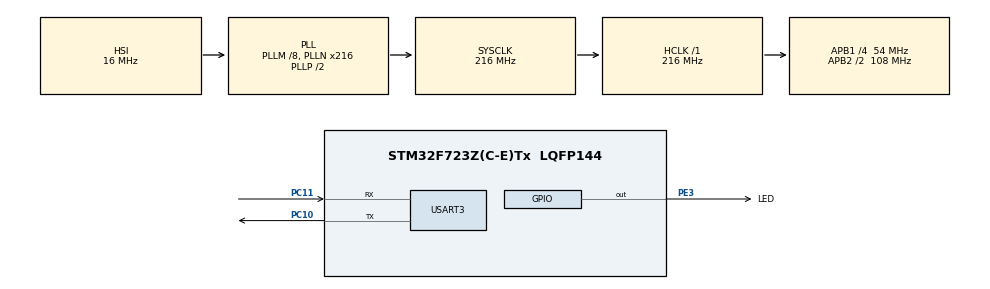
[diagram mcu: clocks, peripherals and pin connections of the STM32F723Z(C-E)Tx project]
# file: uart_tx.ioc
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Dma.Request0=USART3_TX
Dma.USART3_TX.0.Direction=DMA_MEMORY_TO_PERIPH
Dma.USART3_TX.0.FIFOMode=DMA_FIFOMODE_DISABLE
Dma.USART3_TX.0.Instance=DMA1_Stream3
Dma.USART3_TX.0.MemDataAlignment=DMA_MDATAALIGN_BYTE
Dma.USART3_TX.0.MemInc=DMA_MINC_ENABLE
Dma.USART3_TX.0.Mode=DMA_NORMAL
Dma.USART3_TX.0.PeriphDataAlignment=DMA_PDATAALIGN_BYTE
Dma.USART3_TX.0.PeriphInc=DMA_PINC_DISABLE
Dma.USART3_TX.0.Priority=DMA_PRIORITY_LOW
Mcu.Family=STM32F7
Mcu.Name=STM32F723Z(C-E)Tx
Mcu.Package=LQFP144
NVIC.DMA1_Stream3_IRQn=true\:0\:0\:false\:false\:true\:false\:true\:true
NVIC.PriorityGroup=NVIC_PRIORITYGROUP_4
NVIC.USART3_IRQn=true\:0\:0\:false\:false\:true\:true\:true\:true
PC10.Mode=Asynchronous
PC10.Signal=USART3_TX
PC11.Mode=Asynchronous
PC11.Signal=USART3_RX
PE3.GPIO_Label=LED
PE3.Signal=GPIO_Output
PH0-OSC_IN.Mode=HSE-External-Oscillator
PH0-OSC_IN.Signal=RCC_OSC_IN
PH1-OSC_OUT.Mode=HSE-External-Oscillator
PH1-OSC_OUT.Signal=RCC_OSC_OUT
ProjectManager.HeapSize=0x200
ProjectManager.StackSize=0x400
ProjectManager.TargetToolchain=STM32CubeIDE
RCC.AHBFreq_Value=216000000
RCC.APB1CLKDivider=RCC_HCLK_DIV4
RCC.APB1Freq_Value=54000000
RCC.APB1TimFreq_Value=108000000
RCC.APB2CLKDivider=RCC_HCLK_DIV2
RCC.APB2Freq_Value=108000000
RCC.APB2TimFreq_Value=216000000
RCC.CortexFreq_Value=216000000
RCC.HCLKFreq_Value=216000000
RCC.HSE_VALUE=24000000
RCC.HSI_VALUE=16000000
RCC.LSE_VALUE=32768
RCC.PLLM=8
RCC.PLLN=216
RCC.SYSCLKFreq_VALUE=216000000
RCC.SYSCLKSource=RCC_SYSCLKSOURCE_PLLCLK
RCC.USBFreq_Value=216000000
RCC.VCOOutputFreq_Value=432000000
USART3.VirtualMode-Asynchronous=VM_ASYNC
board=custom

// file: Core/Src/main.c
/* USER CODE BEGIN Header */
/**
 ******************************************************************************
 * @file           : main.c
 * @brief          : Main program body
 ******************************************************************************
 * @attention
 *
 * Copyright (c) 2022 STMicroelectronics.
 * All rights reserved.
 *
 * This software is licensed under terms that can be found in the LICENSE file
 * in the root directory of this software component.
 * If no LICENSE file comes with this software, it is provided AS-IS.
 *
 ******************************************************************************
 */

/*
 * Working with tx DMA mode. DMA also works as interrupt, which means data will not block.
 * In DMA when half of the data is transfered a HALF TRANSFER COMPLETE INTERRUPT gets triggered
 * and HAL_UART_TxHalfCpltCallback is called.
 * and when the data cplt,
 * HAL_UART_TxCpltCallback is called.
 *
 * basically the idea behind this is when the second half of the data is is being transferred, we can write new data
 * in the first half.
 */
/* USER CODE END Header */
#include "main.h"

/* USER CODE BEGIN Includes */
#include "serial.h"
#include "led.h"
/* USER CODE END Includes */

UART_HandleTypeDef huart3;
DMA_HandleTypeDef hdma_usart3_tx;

void SystemClock_Config(void);
static void MX_GPIO_Init(void);
static void MX_DMA_Init(void);
static void MX_USART3_UART_Init(void);

/* USER CODE BEGIN 0 */

uint8_t data[2000];
uint8_t count = 0;

void HAL_UART_TxHalfCpltCallback(UART_HandleTypeDef *huart) {
	for (int var = 0; var < 1000; var++) {
		data [var] = 'z';

	}
}

void HAL_UART_TxCpltCallback(UART_HandleTypeDef *huart) {
	for (int var = 1000; var < 2000; var++) {
		data [var] = 'y';

	}
}
/* USER CODE END 0 */

int main(void)
{

  /* MCU Configuration--------------------------------------------------------*/

  /* Reset of all peripherals, Initializes the Flash interface and the Systick. */
  HAL_Init();

  /* Configure the system clock */
  SystemClock_Config();

  /* Initialize all configured peripherals */
  MX_GPIO_Init();
  MX_DMA_Init();
  MX_USART3_UART_Init();
  /* USER CODE BEGIN 2 */

	HAL_UART_Transmit_DMA(&huart3, data, sizeof(data));

	//	for (uint8_t var = 0; var < 2000; var++) {
	//		data[var] = 'x';
	//	}
  /* USER CODE END 2 */

  /* Infinite loop */
  /* USER CODE BEGIN WHILE */
	while (1) {
		// toggle led in every 250 ms
		toggleLED(100);
		count++;
		if ((count % 20) == 0) {
			HAL_UART_Transmit_DMA(&huart3, data, sizeof(data));
		}

    /* USER CODE END WHILE */

	}
}

void SystemClock_Config(void)
{
  RCC_OscInitTypeDef RCC_OscInitStruct = {0};
  RCC_ClkInitTypeDef RCC_ClkInitStruct = {0};

  /** Configure the main internal regulator output voltage
  */
  __HAL_RCC_PWR_CLK_ENABLE();
  __HAL_PWR_VOLTAGESCALING_CONFIG(PWR_REGULATOR_VOLTAGE_SCALE1);

  /** Initializes the RCC Oscillators according to the specified parameters
  * in the RCC_OscInitTypeDef structure.
  */
  RCC_OscInitStruct.OscillatorType = RCC_OSCILLATORTYPE_HSI;
  RCC_OscInitStruct.HSIState = RCC_HSI_ON;
  RCC_OscInitStruct.HSICalibrationValue = RCC_HSICALIBRATION_DEFAULT;
  RCC_OscInitStruct.PLL.PLLState = RCC_PLL_ON;
  RCC_OscInitStruct.PLL.PLLSource = RCC_PLLSOURCE_HSI;
  RCC_OscInitStruct.PLL.PLLM = 8;
  RCC_OscInitStruct.PLL.PLLN = 216;
  RCC_OscInitStruct.PLL.PLLP = RCC_PLLP_DIV2;
  RCC_OscInitStruct.PLL.PLLQ = 2;
  if (HAL_RCC_OscConfig(&RCC_OscInitStruct) != HAL_OK)
  {
    Error_Handler();
  }

  /** Activate the Over-Drive mode
  */
  if (HAL_PWREx_EnableOverDrive() != HAL_OK)
  {
    Error_Handler();
  }

  /** Initializes the CPU, AHB and APB buses clocks
  */
  RCC_ClkInitStruct.ClockType = RCC_CLOCKTYPE_HCLK|RCC_CLOCKTYPE_SYSCLK
                              |RCC_CLOCKTYPE_PCLK1|RCC_CLOCKTYPE_PCLK2;
  RCC_ClkInitStruct.SYSCLKSource = RCC_SYSCLKSOURCE_PLLCLK;
  RCC_ClkInitStruct.AHBCLKDivider = RCC_SYSCLK_DIV1;
  RCC_ClkInitStruct.APB1CLKDivider = RCC_HCLK_DIV4;
  RCC_ClkInitStruct.APB2CLKDivider = RCC_HCLK_DIV2;

  if (HAL_RCC_ClockConfig(&RCC_ClkInitStruct, FLASH_LATENCY_7) != HAL_OK)
  {
    Error_Handler();
  }
}

static void MX_USART3_UART_Init(void)
{

  huart3.Instance = USART3;
  huart3.Init.BaudRate = 115200;
  huart3.Init.WordLength = UART_WORDLENGTH_8B;
  huart3.Init.StopBits = UART_STOPBITS_1;
  huart3.Init.Parity = UART_PARITY_NONE;
  huart3.Init.Mode = UART_MODE_TX_RX;
  huart3.Init.HwFlowCtl = UART_HWCONTROL_NONE;
  huart3.Init.OverSampling = UART_OVERSAMPLING_16;
  huart3.Init.OneBitSampling = UART_ONE_BIT_SAMPLE_DISABLE;
  huart3.AdvancedInit.AdvFeatureInit = UART_ADVFEATURE_NO_INIT;
  if (HAL_UART_Init(&huart3) != HAL_OK)
  {
    Error_Handler();
  }

}

static void MX_DMA_Init(void)
{

  /* DMA controller clock enable */
  __HAL_RCC_DMA1_CLK_ENABLE();

  /* DMA interrupt init */
  /* DMA1_Stream3_IRQn interrupt configuration */
  HAL_NVIC_SetPriority(DMA1_Stream3_IRQn, 0, 0);
  HAL_NVIC_EnableIRQ(DMA1_Stream3_IRQn);

}

static void MX_GPIO_Init(void)
{
  GPIO_InitTypeDef GPIO_InitStruct = {0};

  /* GPIO Ports Clock Enable */
  __HAL_RCC_GPIOE_CLK_ENABLE();
  __HAL_RCC_GPIOH_CLK_ENABLE();
  __HAL_RCC_GPIOC_CLK_ENABLE();

  /*Configure GPIO pin Output Level */
  HAL_GPIO_WritePin(LED_GPIO_Port, LED_Pin, GPIO_PIN_RESET);

  /*Configure GPIO pin : LED_Pin */
  GPIO_InitStruct.Pin = LED_Pin;
  GPIO_InitStruct.Mode = GPIO_MODE_OUTPUT_PP;
  GPIO_InitStruct.Pull = GPIO_NOPULL;
  GPIO_InitStruct.Speed = GPIO_SPEED_FREQ_LOW;
  HAL_GPIO_Init(LED_GPIO_Port, &GPIO_InitStruct);

}

void Error_Handler(void)
{
	__disable_irq();
	while (1) {
	}
}
